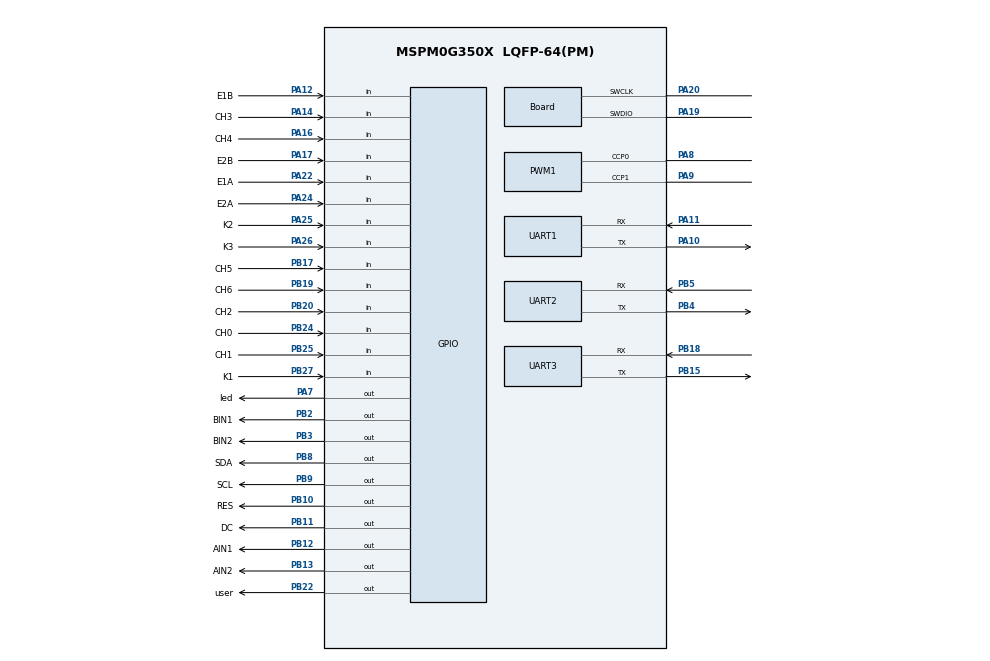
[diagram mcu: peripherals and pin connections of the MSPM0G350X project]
/**
 * @cliArgs --device "MSPM0G350X" --package "LQFP-64(PM)" --part "Default" --product "mspm0_sdk@2.01.00.03"
 * @versions {"tool":"1.20.0+3587"}
 */

/**
 * Import the modules used in this configuration.
 */
const GPIO   = scripting.addModule("/ti/driverlib/GPIO", {}, false);
const GPIO1  = GPIO.addInstance();
const GPIO2  = GPIO.addInstance();
const GPIO3  = GPIO.addInstance();
const GPIO4  = GPIO.addInstance();
const GPIO5  = GPIO.addInstance();
const GPIO6  = GPIO.addInstance();
const GPIO7  = GPIO.addInstance();
const PWM    = scripting.addModule("/ti/driverlib/PWM", {}, false);
const PWM1   = PWM.addInstance();
const SYSCTL = scripting.addModule("/ti/driverlib/SYSCTL");
const TIMER  = scripting.addModule("/ti/driverlib/TIMER", {}, false);
const TIMER1 = TIMER.addInstance();
const TIMER2 = TIMER.addInstance();
const UART   = scripting.addModule("/ti/driverlib/UART", {}, false);
const UART1  = UART.addInstance();
const UART2  = UART.addInstance();
const UART3  = UART.addInstance();

/**
 * Write custom configuration values to the imported modules.
 */
const divider9       = system.clockTree["UDIV"];
divider9.divideValue = 2;

const gate7  = system.clockTree["MFCLKGATE"];
gate7.enable = true;

const multiplier2         = system.clockTree["PLL_QDIV"];
multiplier2.multiplyValue = 5;

const mux8       = system.clockTree["HSCLKMUX"];
mux8.inputSelect = "HSCLKMUX_SYSPLL0";

GPIO1.$name                         = "Motor";
GPIO1.associatedPins.create(4);
GPIO1.associatedPins[0].$name       = "AIN1";
GPIO1.associatedPins[0].pin.$assign = "PB12";
GPIO1.associatedPins[1].$name       = "AIN2";
GPIO1.associatedPins[1].pin.$assign = "PB13";
GPIO1.associatedPins[2].$name       = "BIN1";
GPIO1.associatedPins[2].pin.$assign = "PB2";
GPIO1.associatedPins[3].$name       = "BIN2";
GPIO1.associatedPins[3].pin.$assign = "PB3";

const Board                       = scripting.addModule("/ti/driverlib/Board", {}, false);
Board.peripheral.$assign          = "DEBUGSS";
Board.peripheral.swclkPin.$assign = "PA20";
Board.peripheral.swdioPin.$assign = "PA19";

GPIO2.$name                               = "ENCODERA";
GPIO2.associatedPins.create(2);
GPIO2.associatedPins[0].$name             = "E1A";
GPIO2.associatedPins[0].direction         = "INPUT";
GPIO2.associatedPins[0].polarity          = "RISE";
GPIO2.associatedPins[0].interruptPriority = "0";
GPIO2.associatedPins[0].interruptEn       = true;
GPIO2.associatedPins[0].pin.$assign       = "PA22";
GPIO2.associatedPins[1].$name             = "E1B";
GPIO2.associatedPins[1].direction         = "INPUT";
GPIO2.associatedPins[1].polarity          = "RISE";
GPIO2.associatedPins[1].interruptPriority = "0";
GPIO2.associatedPins[1].interruptEn       = true;
GPIO2.associatedPins[1].pin.$assign       = "PA12";

GPIO3.$name                               = "ENCODERB";
GPIO3.associatedPins.create(2);
GPIO3.associatedPins[0].$name             = "E2A";
GPIO3.associatedPins[0].direction         = "INPUT";
GPIO3.associatedPins[0].polarity          = "RISE";
GPIO3.associatedPins[0].interruptPriority = "0";
GPIO3.associatedPins[0].interruptEn       = true;
GPIO3.associatedPins[0].pin.$assign       = "PA24";
GPIO3.associatedPins[1].$name             = "E2B";
GPIO3.associatedPins[1].direction         = "INPUT";
GPIO3.associatedPins[1].polarity          = "RISE";
GPIO3.associatedPins[1].interruptPriority = "0";
GPIO3.associatedPins[1].interruptEn       = true;
GPIO3.associatedPins[1].pin.$assign       = "PA17";

GPIO4.$name                         = "LED";
GPIO4.associatedPins.create(2);
GPIO4.associatedPins[0].$name       = "led";
GPIO4.associatedPins[0].pin.$assign = "PA7";
GPIO4.associatedPins[1].$name       = "user";
GPIO4.associatedPins[1].pin.$assign = "PB22";

GPIO5.$name                              = "KEY";
GPIO5.associatedPins.create(3);
GPIO5.associatedPins[0].$name            = "K1";
GPIO5.associatedPins[0].direction        = "INPUT";
GPIO5.associatedPins[0].internalResistor = "PULL_UP";
GPIO5.associatedPins[0].pin.$assign      = "PB27";
GPIO5.associatedPins[1].$name            = "K2";
GPIO5.associatedPins[1].direction        = "INPUT";
GPIO5.associatedPins[1].internalResistor = "PULL_UP";
GPIO5.associatedPins[1].pin.$assign      = "PA25";
GPIO5.associatedPins[2].$name            = "K3";
GPIO5.associatedPins[2].direction        = "INPUT";
GPIO5.associatedPins[2].internalResistor = "PULL_UP";
GPIO5.associatedPins[2].pin.$assign      = "PA26";

GPIO6.$name                         = "OLED";
GPIO6.associatedPins.create(4);
GPIO6.associatedPins[0].$name       = "SCL";
GPIO6.associatedPins[0].pin.$assign = "PB9";
GPIO6.associatedPins[1].$name       = "SDA";
GPIO6.associatedPins[1].pin.$assign = "PB8";
GPIO6.associatedPins[2].$name       = "RES";
GPIO6.associatedPins[2].pin.$assign = "PB10";
GPIO6.associatedPins[3].$name       = "DC";
GPIO6.associatedPins[3].pin.$assign = "PB11";

GPIO7.$name                              = "TRACK";
GPIO7.associatedPins.create(7);
GPIO7.associatedPins[0].$name            = "CH0";
GPIO7.associatedPins[0].direction        = "INPUT";
GPIO7.associatedPins[0].internalResistor = "PULL_DOWN";
GPIO7.associatedPins[0].pin.$assign      = "PB24";
GPIO7.associatedPins[1].$name            = "CH1";
GPIO7.associatedPins[1].direction        = "INPUT";
GPIO7.associatedPins[1].internalResistor = "PULL_DOWN";
GPIO7.associatedPins[1].pin.$assign      = "PB25";
GPIO7.associatedPins[2].$name            = "CH2";
GPIO7.associatedPins[2].direction        = "INPUT";
GPIO7.associatedPins[2].internalResistor = "PULL_DOWN";
GPIO7.associatedPins[2].pin.$assign      = "PB20";
GPIO7.associatedPins[3].$name            = "CH3";
GPIO7.associatedPins[3].direction        = "INPUT";
GPIO7.associatedPins[3].internalResistor = "PULL_DOWN";
GPIO7.associatedPins[3].pin.$assign      = "PA14";
GPIO7.associatedPins[4].$name            = "CH4";
GPIO7.associatedPins[4].direction        = "INPUT";
GPIO7.associatedPins[4].internalResistor = "PULL_DOWN";
GPIO7.associatedPins[4].pin.$assign      = "PA16";
GPIO7.associatedPins[5].$name            = "CH5";
GPIO7.associatedPins[5].direction        = "INPUT";
GPIO7.associatedPins[5].internalResistor = "PULL_DOWN";
GPIO7.associatedPins[5].pin.$assign      = "PB17";
GPIO7.associatedPins[6].$name            = "CH6";
GPIO7.associatedPins[6].direction        = "INPUT";
GPIO7.associatedPins[6].internalResistor = "PULL_DOWN";
GPIO7.associatedPins[6].pin.$assign      = "PB19";

PWM1.$name                      = "PWM_0";
PWM1.timerStartTimer            = true;
PWM1.pwmMode                    = "EDGE_ALIGN_UP";
PWM1.timerCount                 = 8000;
PWM1.peripheral.$assign         = "TIMA0";
PWM1.peripheral.ccp0Pin.$assign = "PA8";
PWM1.peripheral.ccp1Pin.$assign = "PA9";
PWM1.PWM_CHANNEL_0.$name        = "ti_driverlib_pwm_PWMTimerCC0";
PWM1.PWM_CHANNEL_1.$name        = "ti_driverlib_pwm_PWMTimerCC1";
PWM1.ccp0PinConfig.$name        = "ti_driverlib_gpio_GPIOPinGeneric4";
PWM1.ccp1PinConfig.$name        = "ti_driverlib_gpio_GPIOPinGeneric5";

SYSCTL.forceDefaultClkConfig = true;
SYSCTL.clockTreeEn           = true;

TIMER1.$name              = "TIMER_0";
TIMER1.timerMode          = "PERIODIC_UP";
TIMER1.timerStartTimer    = true;
TIMER1.timerClkPrescale   = 100;
TIMER1.interrupts         = ["LOAD"];
TIMER1.timerPeriod        = "10ms";
TIMER1.interruptPriority  = "2";
TIMER1.peripheral.$assign = "TIMG6";

TIMER2.$name              = "NTB";
TIMER2.timerMode          = "PERIODIC_UP";
TIMER2.timerStartTimer    = true;
TIMER2.timerClkDiv        = 8;
TIMER2.timerClkSrc        = "MFCLK";
TIMER2.timerPeriod        = "6000 s";
TIMER2.peripheral.$assign = "TIMG12";

UART1.$name                    = "UART_0";
UART1.targetBaudRate           = 115200;
UART1.enabledInterrupts        = ["RX"];
UART1.peripheral.$assign       = "UART0";
UART1.peripheral.rxPin.$assign = "PA11";
UART1.peripheral.txPin.$assign = "PA10";
UART1.txPinConfig.$name        = "ti_driverlib_gpio_GPIOPinGeneric2";
UART1.rxPinConfig.$name        = "ti_driverlib_gpio_GPIOPinGeneric3";

UART2.$name                    = "UART_1";
UART2.targetBaudRate           = 115200;
UART2.enabledInterrupts        = ["RX"];
UART2.peripheral.$assign       = "UART1";
UART2.peripheral.rxPin.$assign = "PB5";
UART2.peripheral.txPin.$assign = "PB4";
UART2.txPinConfig.$name        = "ti_driverlib_gpio_GPIOPinGeneric6";
UART2.rxPinConfig.$name        = "ti_driverlib_gpio_GPIOPinGeneric7";

UART3.$name                    = "UART_2";
UART3.peripheral.$assign       = "UART2";
UART3.peripheral.rxPin.$assign = "PB18";
UART3.peripheral.txPin.$assign = "PB15";
UART3.txPinConfig.$name        = "ti_driverlib_gpio_GPIOPinGeneric0";
UART3.rxPinConfig.$name        = "ti_driverlib_gpio_GPIOPinGeneric1";
